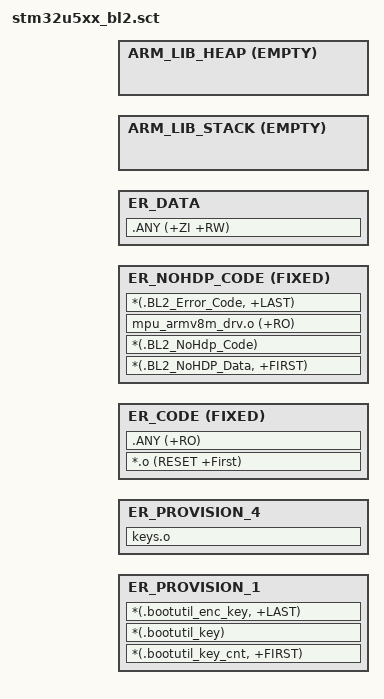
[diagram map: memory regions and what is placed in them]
#! armclang --target=arm-arm-none-eabi -march=armv8-m.main -E -xc

/*
 * Copyright (c) 2017-2018 Arm Limited. All rights reserved.
 *
 * Licensed under the Apache License, Version 2.0 (the "License");
 * you may not use this file except in compliance with the License.
 * You may obtain a copy of the License at
 *
 *     http://www.apache.org/licenses/LICENSE-2.0
 *
 * Unless required by applicable law or agreed to in writing, software
 * distributed under the License is distributed on an "AS IS" BASIS,
 * WITHOUT WARRANTIES OR CONDITIONS OF ANY KIND, either express or implied.
 * See the License for the specific language governing permissions and
 * limitations under the License.
 */

#include "region_defs.h"

LR_CODE PERSO_START {
    ER_PROVISION_1 PERSO_START {
        *(.bootutil_key_cnt, +FIRST)
        *(.bootutil_key)
        *(.bootutil_enc_key, +LAST)
    }
    ER_PROVISION_4 +0  {
        keys.o
    }

    ER_CODE (BL2_CODE_START) FIXED (BL2_CODE_SIZE) {
        *.o (RESET +First)
        .ANY (+RO)
    }

    ER_NOHDP_CODE (BL2_NOHDP_CODE_START) FIXED (BL2_NOHDP_CODE_SIZE) {
        *(.BL2_NoHDP_Data, +FIRST)
        *(.BL2_NoHdp_Code)
        mpu_armv8m_drv.o (+RO)
        *(.BL2_Error_Code, +LAST)
    }

    ER_DATA (BL2_DATA_START) (BL2_DATA_SIZE-BL2_MSP_STACK_SIZE-BL2_HEAP_SIZE) {
        .ANY (+ZI +RW)
    }

    /* MSP */
    ARM_LIB_STACK +0 ALIGN 32 EMPTY BL2_MSP_STACK_SIZE {
    }

    ARM_LIB_HEAP +0 ALIGN 8 EMPTY BL2_HEAP_SIZE {
    }
}
